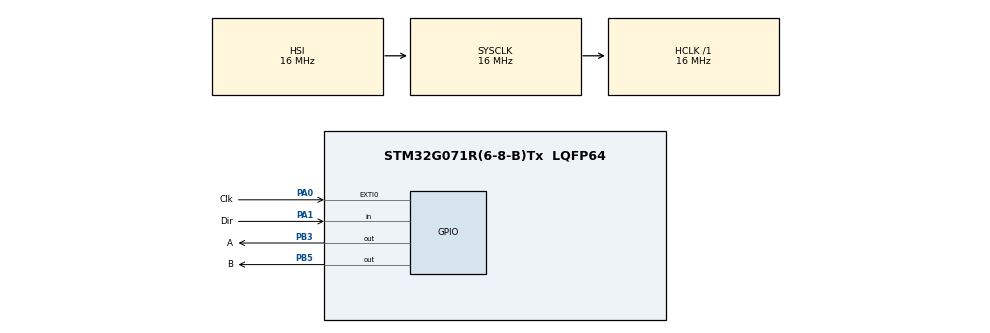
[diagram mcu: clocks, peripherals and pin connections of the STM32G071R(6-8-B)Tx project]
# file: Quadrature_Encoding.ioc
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Mcu.Family=STM32G0
Mcu.Name=STM32G071R(6-8-B)Tx
Mcu.Package=LQFP64
NVIC.EXTI0_1_IRQn=true\:0\:0\:false\:false\:true\:true\:true\:true
PA0.GPIO_Label=Clk
PA0.Signal=GPXTI0
PA1.GPIO_Label=Dir
PA1.Signal=GPIO_Input
PA13.Mode=Serial_Wire
PA13.Signal=SYS_SWDIO
PA14-BOOT0.Mode=Serial_Wire
PA14-BOOT0.Signal=SYS_SWCLK
PB3.GPIO_Label=A
PB3.Signal=GPIO_Output
PB5.GPIO_Label=B
PB5.Signal=GPIO_Output
ProjectManager.HeapSize=0x200
ProjectManager.StackSize=0x400
ProjectManager.TargetToolchain=STM32CubeIDE
RCC.AHBFreq_Value=16000000
RCC.CortexFreq_Value=16000000
RCC.EXTERNAL_CLOCK_VALUE=48000
RCC.HCLKFreq_Value=16000000
RCC.HSE_VALUE=8000000
RCC.HSI_VALUE=16000000
RCC.LSE_VALUE=32768
RCC.SYSCLKFreq_VALUE=16000000
RCC.VCOOutputFreq_Value=128000000
board=custom

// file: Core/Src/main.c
/* USER CODE BEGIN Header */
/**
  ******************************************************************************
  * @file           : main.c
  * @brief          : Main program body
  ******************************************************************************
  * @attention
  *
  * Copyright (c) 2024 STMicroelectronics.
  * All rights reserved.
  *
  * This software is licensed under terms that can be found in the LICENSE file
  * in the root directory of this software component.
  * If no LICENSE file comes with this software, it is provided AS-IS.
  *
  ******************************************************************************
  */
/* USER CODE END Header */
#include "main.h"
#include "FSM.h"

void SystemClock_Config(void);
static void MX_GPIO_Init(void);

/* USER CODE BEGIN 0 */
FSMType fsm;

/* USER CODE END 0 */

int main(void)
{

  /* MCU Configuration--------------------------------------------------------*/

  /* Reset of all peripherals, Initializes the Flash interface and the Systick. */
  HAL_Init();

  /* Configure the system clock */
  SystemClock_Config();

  /* Initialize all configured peripherals */
  MX_GPIO_Init();
  /* USER CODE BEGIN 2 */
  InitializeFSM(&fsm);
  /* USER CODE END 2 */

  /* Infinite loop */
  while (1)
  {

	  HAL_GPIO_WritePin(A_GPIO_Port, A_Pin, (OutputFunction(&fsm) & 0x02) ? GPIO_PIN_SET : GPIO_PIN_RESET);
      HAL_GPIO_WritePin(B_GPIO_Port, B_Pin, (OutputFunction(&fsm) & 0x01) ? GPIO_PIN_SET : GPIO_PIN_RESET);
  }
}

void SystemClock_Config(void)
{
  RCC_OscInitTypeDef RCC_OscInitStruct = {0};
  RCC_ClkInitTypeDef RCC_ClkInitStruct = {0};

  /** Configure the main internal regulator output voltage
  */
  HAL_PWREx_ControlVoltageScaling(PWR_REGULATOR_VOLTAGE_SCALE1);

  /** Initializes the RCC Oscillators according to the specified parameters
  * in the RCC_OscInitTypeDef structure.
  */
  RCC_OscInitStruct.OscillatorType = RCC_OSCILLATORTYPE_HSI;
  RCC_OscInitStruct.HSIState = RCC_HSI_ON;
  RCC_OscInitStruct.HSIDiv = RCC_HSI_DIV1;
  RCC_OscInitStruct.HSICalibrationValue = RCC_HSICALIBRATION_DEFAULT;
  RCC_OscInitStruct.PLL.PLLState = RCC_PLL_NONE;
  if (HAL_RCC_OscConfig(&RCC_OscInitStruct) != HAL_OK)
  {
    Error_Handler();
  }

  /** Initializes the CPU, AHB and APB buses clocks
  */
  RCC_ClkInitStruct.ClockType = RCC_CLOCKTYPE_HCLK|RCC_CLOCKTYPE_SYSCLK
                              |RCC_CLOCKTYPE_PCLK1;
  RCC_ClkInitStruct.SYSCLKSource = RCC_SYSCLKSOURCE_HSI;
  RCC_ClkInitStruct.AHBCLKDivider = RCC_SYSCLK_DIV1;
  RCC_ClkInitStruct.APB1CLKDivider = RCC_HCLK_DIV1;

  if (HAL_RCC_ClockConfig(&RCC_ClkInitStruct, FLASH_LATENCY_0) != HAL_OK)
  {
    Error_Handler();
  }
}

static void MX_GPIO_Init(void)
{
  GPIO_InitTypeDef GPIO_InitStruct = {0};

  /* GPIO Ports Clock Enable */
  __HAL_RCC_GPIOA_CLK_ENABLE();
  __HAL_RCC_GPIOB_CLK_ENABLE();

  /*Configure GPIO pin Output Level */
  HAL_GPIO_WritePin(GPIOB, A_Pin|B_Pin, GPIO_PIN_RESET);

  /*Configure GPIO pin : Clk_Pin */
  GPIO_InitStruct.Pin = Clk_Pin;
  GPIO_InitStruct.Mode = GPIO_MODE_IT_RISING;
  GPIO_InitStruct.Pull = GPIO_NOPULL;
  HAL_GPIO_Init(Clk_GPIO_Port, &GPIO_InitStruct);

  /*Configure GPIO pin : Dir_Pin */
  GPIO_InitStruct.Pin = Dir_Pin;
  GPIO_InitStruct.Mode = GPIO_MODE_INPUT;
  GPIO_InitStruct.Pull = GPIO_NOPULL;
  HAL_GPIO_Init(Dir_GPIO_Port, &GPIO_InitStruct);

  /*Configure GPIO pins : A_Pin B_Pin */
  GPIO_InitStruct.Pin = A_Pin|B_Pin;
  GPIO_InitStruct.Mode = GPIO_MODE_OUTPUT_PP;
  GPIO_InitStruct.Pull = GPIO_NOPULL;
  GPIO_InitStruct.Speed = GPIO_SPEED_FREQ_LOW;
  HAL_GPIO_Init(GPIOB, &GPIO_InitStruct);

  /* EXTI interrupt init*/
  HAL_NVIC_SetPriority(EXTI0_1_IRQn, 0, 0);
  HAL_NVIC_EnableIRQ(EXTI0_1_IRQn);

}

/* USER CODE BEGIN 4 */
void HAL_GPIO_EXTI_Rising_Callback(uint16_t GPIO_Pin)

{
	fsm.CurrentInput = (HAL_GPIO_ReadPin(Dir_GPIO_Port, Dir_Pin) == GPIO_PIN_SET) ? COUNTERCW : CLOCKWISE;
	fsm.CurrentState = NextStateFunctionPointers(&fsm);
}

/* USER CODE END 4 */

void Error_Handler(void)
{
  __disable_irq();
  while (1)
  {
  }
}
